# NPCX490M register map
File version: 1.0
Registers are 8-bit, read-write, reset 0x0 unless marked. A register's access mark holds for its fields unless they carry their own. Offsets are from the block's base; [hi:lo] are bit positions.

## ITIM64
Base 0x400BE000
0x01 ITPRE64 — Internal Timer Prescaler Register (ITPRE64)
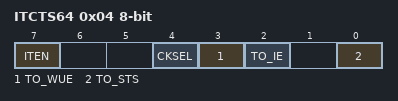
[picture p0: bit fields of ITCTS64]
0x04 ITCTS64 — Internal Timer Control and Status Register (ITCTS64)
  [7] ITEN — ITIM64 Module Enable
  [4] CKSEL — Input Clock Select
  [3] TO_WUE — Timeout Wake-up Enable
  [2] TO_IE — Timeout Interrupt Enable
  [0] TO_STS — Timeout Status
0x08 ITCNT64L 32-bit (reset mask 0xFF) — Internal 64-Bit Timer Counter Register, Low DWord (ITCNT64L)
0x0C ITCNT64H 32-bit (reset mask 0xFF) — Internal 64-Bit Timer Counter Register, High DWord (ITCNT64H)

## KBC
Base 0x400C7000
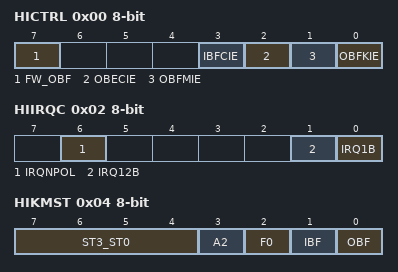
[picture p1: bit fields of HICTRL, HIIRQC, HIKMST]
0x00 HICTRL — Host Interface Control Register (HICTRL)
  [7] FW_OBF — Firmware Control Over OBF
  [3] IBFCIE — Input Buffer Full Core Interrupt Enable
  [2] OBECIE — Output Buffer Empty Core Interrupt Enable
  [1] OBFMIE — Output Buffer Full Mouse Interrupt Enable
  [0] OBFKIE — Output Buffer Full Keyboard Interrupt Enable
0x02 HIIRQC — Host Interface IRQ Control Register (HIIRQC)
  [6] IRQNPOL — Negative Polarity
  [1] IRQ12B — Host Interrupt Request 12 Control Bit
  [0] IRQ1B — Host Interrupt Request 1 Control Bit
0x04 HIKMST — Host Interface Keyboard/Mouse Status Register (HIKMST)
  [7:4] ST3_ST0 — Status Bits
  [3] A2 — A2 Address
  [2] F0 — Flag 0
  [1] IBF — Input Buffer Full
  [0] OBF — Output Buffer Full
0x06 HIKDO — Host Interface Keyboard Data Out Buffer Register (HIKDO)
0x08 HIMDO — Host Interface Mouse Data Out Buffer Register (HIMDO)
0x0A HIKMDI — Host Interface Keyboard/Mouse Data In Buffer Register (HIKMDI)
0x0B SHIKMDI — Host Interface Keyboard/Mouse Shadow Data In Buffer Register (SHIKMDI)

## KBS
Base 0x400A3000
0x00 KBSBUF0-17 — Keyboard Scan Buffer Data 0-17 Register (KBSBUF0-17)
0x00 KBS_DLY1 — Keyboard Scan Delay 1 Register (KBS_DLY1)
0x01 KBS_DLY2 — Keyboard Scan Delay 2 Register (KBS_DLY2)
0x02 KBS_RTYTO — Keyboard Scan Retry Timeout Register (KBS_RTYTO)
0x03 KBS_CNUM — Keyboard Scan Columns Number Register (KBS_CNUM)
  [4:0] KBS_COL_NUM — Keyboard Scan Columns Number
0x04 KBSIN — Keyboard Scan In Register (KBSIN)
0x04 KBS_CDIV — Keyboard Scan Clock Divisor Register (KBS_CDIV)
  [5:0] KBS_CLK_DIV — Keyboard Scan Clock Divisor
0x05 KBSINPU — Keyboard Scan In Pull-Up Enable Register (KBSINPU)
0x06 KBSOUT0 16-bit (reset mask 0xFF) — Keyboard Scan Out 0 Register (KBSOUT0)
0x08 KBSOUT1 16-bit — Keyboard Scan Out 1 Register (KBSOUT1)
  [1:0] KBSOUT17_KBSOUT16 — Keyboard Scan Out Bits 17-16
0x0A KBS_BUF_INDX — Keyboard Scan Buffer Index Register (KBS_BUF_INDX)
  [4:0] KBS_BUF_INDX — Keyboard Scan Buffer Index
0x0B KBS_BUF_DATA — Keyboard Scan Buffer Data Register (KBS_BUF_DATA)
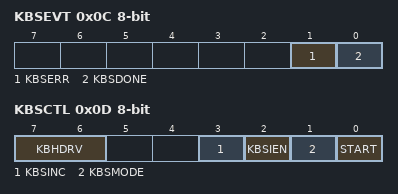
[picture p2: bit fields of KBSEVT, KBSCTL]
0x0C KBSEVT — Keyboard Scan Event Register (KBSEVT)
  [1] KBSERR — Keyboard Scan Error
  [0] KBSDONE — Keyboard Scan Done Indication
0x0D KBSCTL — Keyboard Scan Control Register (KBSCTL)
  [7:6] KBHDRV — Keyboard Outputs High Drive
  [3] KBSINC — Keyboard Scan Index Increment
  [2] KBSIEN — Keyboard Scan Interrupt Enable
  [1] KBSMODE — Keyboard Scan Mode
  [0] START — Automatic Keyboard Scan Start
0x0E KBS_CFG_INDX — Keyboard Scan Configuration Index Register (KBS_CFG_INDX)
  [4:0] KBS_CFG_INDX — Keyboard Scan Configuration Index
0x0F KBS_CFG_DATA — Keyboard Scan Configuration Data Register (KBS_CFG_DATA)

## LCT
Base 0x400D7000
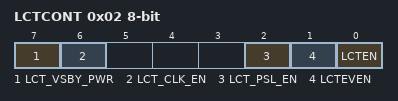
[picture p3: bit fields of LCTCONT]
0x02 LCTCONT — LCT Control Register (LCTCONT)
  [7] LCT_VSBY_PWR — LCT, VSBY Power Select
  [6] LCT_CLK_EN — LCT Clock Enable
  [2] LCT_PSL_EN — LCT PSL Event Enable
  [1] LCTEVEN — LCT Event Enable
  [0] LCTEN — LCT Enable
0x04 LCTSTAT — LCT Status Register (LCTSTAT)
  [0] LCTEVST — LCT Event Status
0x05 LCTSECOND — LCT Seconds Register (LCTSECOND)
0x06 LCTMINUT — LCT Minutes Register (LCTMINUT)
0x08 LCTHOUR — LCT Hours Register (LCTHOUR)
  [4:0] HOURS — Hours Value
0x0A LCTDAY — LCT Days Register (LCTDAY)
  [4:0] DAYS — Days Value
0x0C LCTWEEK — LCT Weeks LSB Register (LCTWEEK)
0x0D LCTWEEKM — LCT Weeks MSB Register (LCTWEEKM)
  [2:0] WEEKS — Weeks Value
